# CM0+ register map
CPU: CM0+ r0p0, selectable endian, MPU, no FPU, 2 interrupt priority bits
Registers are 32-bit, read-write, reset 0x0 unless marked. A register's access mark holds for its fields unless they carry their own. Offsets are from the block's base; lines under a group give offsets from that group; [hi:lo] are bit positions; {n}, {i} and the like mark numbered series; 'fields as' and 'values as' point back to an identical list; <NAME> marks a mode.

## Memory map
0xE0001000 DWT size 0x1000 — Data Watchpoint and Trace
0xE0002000 BPU size 0x1000 — Breakpoint Unit
0xE000E008 ICB size 0xC — Implementation Control Block
0xE000E010 SYSTICK size 0x10 — SysTick Timer
0xE000E100 NVIC size 0x320 — Nested Vectored Interrupt Controller
0xE000ED00 SCB size 0x90 — System Control Block
0xE000ED90 MPU size 0x2C — Memory Protection Unit
0xE000EDF0 DCB size 0x10 — Debug Control Block

## DWT — Data Watchpoint and Trace
Base 0xE0001000
0x00 Control register ro — Provides configuration and status information for the DWT unit, and used to control features of the unit
  [31:28] NUMCOMP — Number of comparators implemented
0x1C Program Counter Sample Register ro — Samples the current value of the program counter
  [31:0] EIASAMPLE — Executed Instruction Address sample value
{0x20+4i} Comparator register[{i}] (i=0..7) — Provides a reference value for use by comparator n
  [31:0] COMP — Reference value for comparison
{0x24+4i} Comparator Mask register {i} (i=0..7) — Provides the size of the ignore mask applied to the access address for address range matching by comparator n
  [4:0] MASK — The size of the ignore mask, 0-31 bits, applied to address range matching
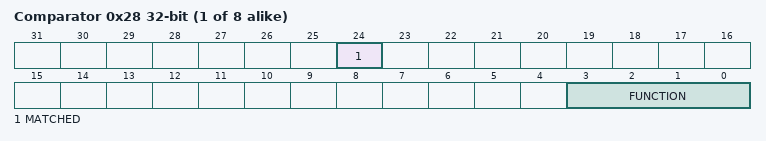
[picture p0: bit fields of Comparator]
{0x28+4i} Comparator Function register {i} (i=0..7) — Controls the operation of comparator n
  [24] MATCHED — Comparator match
    0=No match; 1=Match
  [3:0] FUNCTION — Selects action taken on comparator match

## BPU — Breakpoint Unit
Base 0xE0002000
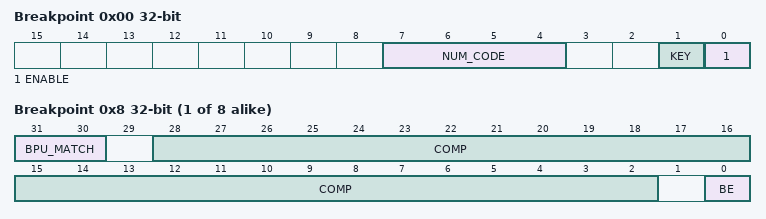
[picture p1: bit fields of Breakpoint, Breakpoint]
0x00 Breakpoint Control Register — Provides BPU implementation information, and the global enable for the BPU
  [7:4] NUM_CODE — The number of breakpoint comparators
  [1] KEY — On any write to FP_CTRL, this bit must be 1
  [0] ENABLE — Enable bit for the FPB
    0=Flash Patch Breakpoint disabled; 1=Flash Patch Breakpoint enabled
{0x8+4i} Breakpoint Comparator Register {i} (i=0..7) — Holds a breakpoint address for comparison with instruction addresses in the Code memory region
  [31:30] BPU_MATCH — defines the behavior when the COMP address is matched
    0=no breakpoint matching; 1=Breakpoint on lower halfword, upper is unaffected; 10=Breakpoint on upper halfword, lower is unaffected; 11=Breakpoint on both lower and upper halfwords
  [28:2] COMP — Stores bits [28:2] of the comparison address
  [0] BE — enables the comperator
    0=Disabled; 1=Enabled

## ICB — Implementation Control Block
Base 0xE000E008
0x00 Auxiliary Control Register — Provides IMPLEMENTATION DEFINED configuration and control options

## SYSTICK — SysTick Timer
Base 0xE000E010
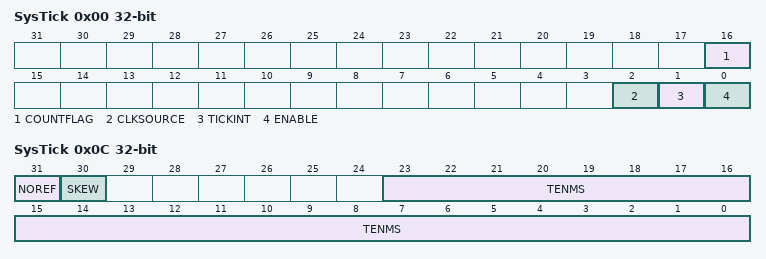
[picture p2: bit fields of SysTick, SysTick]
0x00 SysTick Control and Status Register — Controls the system timer and provides status data
  [16] COUNTFLAG — Indicates whether the counter has counted to 0 since the last read of this register
    0=Timer has not counted to 0; 1=Timer has counted to 0
  [2] CLKSOURCE — Indicates the SysTick clock source
    0=external (SysTick uses the IMPLEMENTATION DEFINED external reference clock); 1=processor (SysTick uses the processor clock)
  [1] TICKINT — Indicates whether counting to 0 causes the status of the SysTick exception to change to pending
    0=interrupt_disabled (Count to 0 does not affect the SysTick exception status); 1=interrupt_enabled (Count to 0 changes the SysTick exception status to pending)
  [0] ENABLE — Indicates the enabled status of the SysTick counter
    0=Counter is disabled; 1=Counter is operating
0x04 SysTick Reload Value Register — Holds the reload value of the SYSTICK_CVR
  [23:0] RELOAD — The value to load into the SYSTICK_CVR when the counter reaches 0
0x08 SysTick Current Value Register — Reads or clears the current counter value
  [31:0] CURRENT — Current counter value
0x0C SysTick Calibration value Register ro — Reads the calibration value and parameters for SysTick
  [31] NOREF — Indicates whether the IMPLEMENTATION DEFINED reference clock is implemented
    0=The reference clock is implemented; 1=The reference clock is not implemented
  [30] SKEW — Indicates whether the 10ms calibration value is exact
    0=10ms calibration value is exact; 1=10ms calibration value is inexact, because of the clock frequency
  [23:0] TENMS — Optionally, holds a reload value to be used for 10ms (100Hz) timing, subject to system clock skew errors
